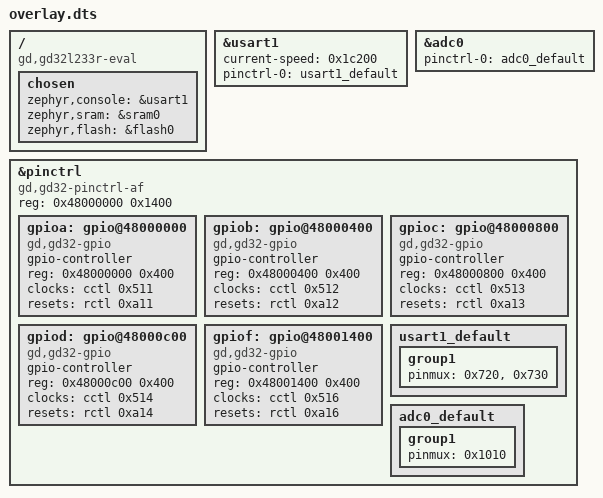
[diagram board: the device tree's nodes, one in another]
/ {
	compatible = "gd,gd32l233r-eval";
	chosen {
		zephyr,console = &usart1;
		zephyr,sram = &sram0;
		zephyr,flash = &flash0;
	};
};
&gpiod{
	status = "okay";
};
&usart1{
	status = "okay";
	current-speed = < 0x1c200 >;
	pinctrl-0 = < &usart1_default >;
	pinctrl-names = "default";
};
&gpiob{
	status = "okay";
};
&gpioc{
	status = "okay";
};
&gpioa{
	status = "okay";
};
&gpiof{
	status = "okay";
};
&adc0{
	status = "okay";
	pinctrl-0 = < &adc0_default >;
	pinctrl-names = "default";
};
&pinctrl{
	compatible = "gd,gd32-pinctrl-af";
	reg = < 0x48000000 0x1400 >;
	#address-cells = < 0x1 >;
	#size-cells = < 0x1 >;
	status = "okay";
	gpioa: gpio@48000000 {
		compatible = "gd,gd32-gpio";
		gpio-controller;
		#gpio-cells = < 0x2 >;
		reg = < 0x48000000 0x400 >;
		clocks = < &cctl 0x511 >;
		resets = < &rctl 0xa11 >;
		status = "okay";
	};
	gpiob: gpio@48000400 {
		compatible = "gd,gd32-gpio";
		gpio-controller;
		#gpio-cells = < 0x2 >;
		reg = < 0x48000400 0x400 >;
		clocks = < &cctl 0x512 >;
		resets = < &rctl 0xa12 >;
		status = "okay";
	};
	gpioc: gpio@48000800 {
		compatible = "gd,gd32-gpio";
		gpio-controller;
		#gpio-cells = < 0x2 >;
		reg = < 0x48000800 0x400 >;
		clocks = < &cctl 0x513 >;
		resets = < &rctl 0xa13 >;
		status = "okay";
	};
	gpiod: gpio@48000c00 {
		compatible = "gd,gd32-gpio";
		gpio-controller;
		#gpio-cells = < 0x2 >;
		reg = < 0x48000c00 0x400 >;
		clocks = < &cctl 0x514 >;
		resets = < &rctl 0xa14 >;
		status = "okay";
	};
	gpiof: gpio@48001400 {
		compatible = "gd,gd32-gpio";
		gpio-controller;
		#gpio-cells = < 0x2 >;
		reg = < 0x48001400 0x400 >;
		clocks = < &cctl 0x516 >;
		resets = < &rctl 0xa16 >;
		status = "okay";
	};
	usart1_default: usart1_default {
		group1 {
			pinmux = < 0x720 >, < 0x730 >;
		};
	};
	adc0_default: adc0_default {
		group1 {
			pinmux = < 0x1010 >;
		};
	};
};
